# DECODER0_MSVDX_VDEB register map
Vendor: Texas Instruments
Peripheral module from a debugger description file (folder J7ES).
Registers are 32-bit, read-only, reset 0x0 unless marked. A register's access mark holds for its fields unless they carry their own. Offsets are as the file gives them; lines under a group give offsets from that group; [hi:lo] are bit positions; {n}, {i} and the like mark numbered series; 'fields as' and 'values as' point back to an identical list; <NAME> marks a mode.

## DECODER0_MSVDX_VDEB
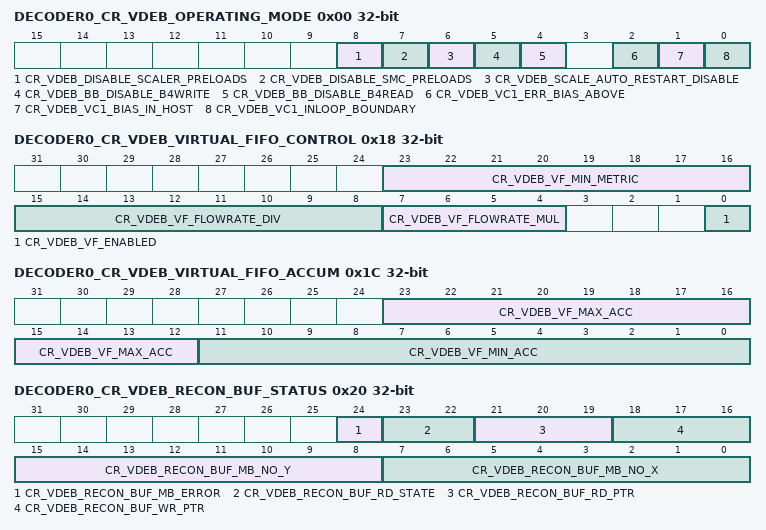
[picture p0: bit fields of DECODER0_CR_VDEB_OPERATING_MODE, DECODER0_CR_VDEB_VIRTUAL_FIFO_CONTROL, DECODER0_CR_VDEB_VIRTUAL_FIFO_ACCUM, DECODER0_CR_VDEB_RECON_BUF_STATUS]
0x00 DECODER0_CR_VDEB_OPERATING_MODE rw — VDEB operating mode. Used to alter operation implied by the codec mode
  [8] CR_VDEB_DISABLE_SCALER_PRELOADS — Disable MMU page preloads from the Alternative buffer [Scaler or rotation output]
  [7] CR_VDEB_DISABLE_SMC_PRELOADS — Disable MMU page preloads from the SMC.
  [6] CR_VDEB_SCALE_AUTO_RESTART_DISABLE — Disable Scaler auto restart.
  [5] CR_VDEB_BB_DISABLE_B4WRITE — Disable burst4 writes generated in the burst buffer.
  [4] CR_VDEB_BB_DISABLE_B4READ — Disable burst4 reads generated in the burst buffer.
  [2] CR_VDEB_VC1_ERR_BIAS_ABOVE — For error concealment force bias/clip of above data
  [1] CR_VDEB_VC1_BIAS_IN_HOST — Bias and clip filtering may be performed by the host or in hardware
  [0] CR_VDEB_VC1_INLOOP_BOUNDARY — VC1 In-loop boundary flags may be supplied via command for in-loop deblock filtering
0x04 DECODER0_CR_VDEB_PREFETCH_FIFO rw — VDEB Pre-fetch FIFO control and status
  [0] CR_VDEB_PREFETCH_FIFO_DISABLED — Use of Pre-fetch FIFO may be disabled for error handling
0x08 DECODER0_CR_VDEB_SYS_MEM_RDATA_LUMA_SIGNATURE
  [31:0] CR_VDEB_SYS_MEM_RDATA_LUMA_SIGNATURE — VDEB signature analysis on the system-memory luma read-data bus
0x0C DECODER0_CR_VDEB_SYS_MEM_RDATA_CHROMA_SIGNATURE
  [31:0] CR_VDEB_SYS_MEM_RDATA_CHROMA_SIGNATURE — VDEB signature analysis on the system-memory chroma read-data bus
0x10 DECODER0_CR_VDEB_SYS_MEM_ADDR_SIGNATURE — The address signature includes a base address id added to the bottom 3 bits of the signature input. The id is as follows 0x0: Chroma2 reconstructed 0x1: Luma reconstructed 0x2: Chroma reconstructed 0x3: Aux MSB buffer 0x4: Aux Line buffer 0x5: Luma alternate 0x6: Chroma alternate 0x7: Chroma2 alternate
  [31:0] CR_VDEB_SYS_MEM_ADDR_SIGNATURE — VDEB signature analysis on the system-memory address bus
0x14 DECODER0_CR_VDEB_SYS_MEM_WDATA_SIGNATURE
  [31:0] CR_VDEB_SYS_MEM_WDATA_SIGNATURE — VDEB signature analysis on the system-memory write-data bus
0x18 DECODER0_CR_VDEB_VIRTUAL_FIFO_CONTROL rw — The Virtual FIFO enables dynamic control of the 'Time to Expire' output for the system memory interface
  [23:16] CR_VDEB_VF_MIN_METRIC — The minimum value of the 'time to expire metric'
  [15:8] CR_VDEB_VF_FLOWRATE_DIV — Virtual FIFO divisor control.
  [7:4] CR_VDEB_VF_FLOWRATE_MUL — Virtual FIFO multiple control.
  [0] CR_VDEB_VF_ENABLED — Enable the Virtual FIFO
0x1C DECODER0_CR_VDEB_VIRTUAL_FIFO_ACCUM rw — Virtual FIFO flow rate accumulator defines the effective size and the number of words of deficit in the data flow that can be controlled
  [23:12] CR_VDEB_VF_MAX_ACC — Virtual FIFO max internal accumulator value defines the upper range for the accumulator which prevents the metric getting set unrealistically high
  [11:0] CR_VDEB_VF_MIN_ACC — Virtual FIFO min internal accumulator value defines the lower range for the accumulator, allowing a low priority to be applied to all
0x20 DECODER0_CR_VDEB_RECON_BUF_STATUS
  [24] CR_VDEB_RECON_BUF_MB_ERROR — Recon Buf MB Error flag - MB has been marked as with an error
  [23:22] CR_VDEB_RECON_BUF_RD_STATE — Recon Buf internal read state
  [21:19] CR_VDEB_RECON_BUF_RD_PTR — Recon Buf read pointer
  [18:16] CR_VDEB_RECON_BUF_WR_PTR — Recon Buf write pointer
  [15:8] CR_VDEB_RECON_BUF_MB_NO_Y — Recon Buf macroblock number Y
  [7:0] CR_VDEB_RECON_BUF_MB_NO_X — Recon Buf macroblock number X
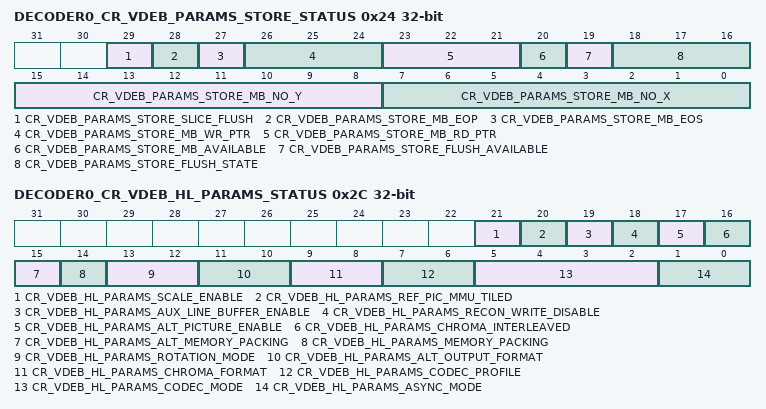
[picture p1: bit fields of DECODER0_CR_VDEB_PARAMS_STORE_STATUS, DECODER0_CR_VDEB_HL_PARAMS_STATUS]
0x24 DECODER0_CR_VDEB_PARAMS_STORE_STATUS
  [29] CR_VDEB_PARAMS_STORE_SLICE_FLUSH — Param Store slice flush
  [28] CR_VDEB_PARAMS_STORE_MB_EOP — Param Store macroblock end of picture
  [27] CR_VDEB_PARAMS_STORE_MB_EOS — Param Store macroblock end of slice
  [26:24] CR_VDEB_PARAMS_STORE_MB_WR_PTR — Param Store macroblock write pointer
  [23:21] CR_VDEB_PARAMS_STORE_MB_RD_PTR — Param Store macroblock read pointer
  [20] CR_VDEB_PARAMS_STORE_MB_AVAILABLE — Param Store macroblock available
  [19] CR_VDEB_PARAMS_STORE_FLUSH_AVAILABLE — Param Store flush available
  [18:16] CR_VDEB_PARAMS_STORE_FLUSH_STATE — Param Store Flush state
  [15:8] CR_VDEB_PARAMS_STORE_MB_NO_Y — Param Store macroblock number Y
  [7:0] CR_VDEB_PARAMS_STORE_MB_NO_X — Param Store macroblock number X
0x28 DECODER0_CR_VDEB_SLICE_INTERRUPT_COUNT — Register to keep track of interrupts generated
  [2:0] CR_VDEB_SLICE_INTERRUPT_COUNT — Wrapping counter incremented every end of slice interrupt
0x2C DECODER0_CR_VDEB_HL_PARAMS_STATUS — Register to keep track of internal setup programmed via firmware or otherwise inaccesible values:
  [21] CR_VDEB_HL_PARAMS_SCALE_ENABLE — Scale Enable
  [20] CR_VDEB_HL_PARAMS_REF_PIC_MMU_TILED — Ref Pic MMU Tiled
  [19] CR_VDEB_HL_PARAMS_AUX_LINE_BUFFER_ENABLE — Auxiliary Line Buffer Enable
  [18] CR_VDEB_HL_PARAMS_RECON_WRITE_DISABLE — Recon Write Disable
  [17] CR_VDEB_HL_PARAMS_ALT_PICTURE_ENABLE — Alternative Picture Enable
  [16] CR_VDEB_HL_PARAMS_CHROMA_INTERLEAVED — Chroma Interleaved
  [15] CR_VDEB_HL_PARAMS_ALT_MEMORY_PACKING — Alternative Memory Packing
  [14] CR_VDEB_HL_PARAMS_MEMORY_PACKING — Memory Packing
  [13:12] CR_VDEB_HL_PARAMS_ROTATION_MODE — Rotation Mode
  [11:10] CR_VDEB_HL_PARAMS_ALT_OUTPUT_FORMAT — Alternative Output Format
  [9:8] CR_VDEB_HL_PARAMS_CHROMA_FORMAT — Chroma Format
  [7:6] CR_VDEB_HL_PARAMS_CODEC_PROFILE — Codec Profile
  [5:2] CR_VDEB_HL_PARAMS_CODEC_MODE — Codec Mode
  [1:0] CR_VDEB_HL_PARAMS_ASYNC_MODE — Async Mode
0x30 DECODER0_CR_VDEB_BLOCK_MEM_DIAGNOSTICS
  [31:0] CR_VDEB_BLOCK_MEM_DIAGNOSTICS — VDEB block_mem diagnostics [debug use only]
0x34 DECODER0_CR_VDEB_PARAMS_DIAGNOSTICS
  [31:0] CR_VDEB_PARAMS_DIAGNOSTICS — VDEB param-store diagnostics [debug use only]
0x38 DECODER0_CR_VDEB_FILTER_DIAGNOSTICS
  [31:0] CR_VDEB_FILTER_DIAGNOSTICS — VDEB filter diagnostics [debug use only]
0x3C DECODER0_CR_VDEB_MAIN_DIAGNOSTICS reset 0xB000
  [31:0] CR_VDEB_MAIN_DIAGNOSTICS — VDEB main-control diagnostics [debug use only]
0x40 DECODER0_CR_VDEB_SYS_MEM_ADDR_WR_LUMA_SIGNATURE — The address signature includes a base address id added to the bottom 3 bits of the signature input. The id is as follows 0x1: Luma reconstructed 0x3: Aux MSB buffer 0x4: Aux Line buffer 0x5: Luma alternate
  [31:0] CR_VDEB_SYS_MEM_ADDR_WR_LUMA_SIGNATURE — VDEB signature analysis on the system-memory addr bus for luma
0x44 DECODER0_CR_VDEB_SYS_MEM_ADDR_WR_CHROMA_SIGNATURE — The address signature includes a base address id added to the bottom 3 bits of the signature input. The id is as follows 0x0: Chroma2 reconstructed 0x2: Chroma reconstructed 0x3: Aux MSB buffer 0x4: Aux Line buffer 0x6: Chroma alternate 0x7: Chroma2 alternate
  [31:0] CR_VDEB_SYS_MEM_ADDR_WR_CHROMA_SIGNATURE — VDEB signature analysis on the system-memory addr bus for chroma
0x48 DECODER0_CR_VDEB_SCALE_ADDR_SIGNATURE — The address signature includes a base address id added to the bottom 3 bits of the signature input. The id is as follows 0x0: Chroma2 reconstructed 0x1: Luma reconstructed 0x2: Chroma reconstructed 0x3: Aux MSB buffer 0x4: Aux Line buffer 0x5: Luma alternate 0x6: Chroma alternate 0x7: Chroma2 alternate
  [31:0] CR_VDEB_SCALE_ADDR_SIGNATURE — VDEB signature analysis on the scale address bus
0x4C DECODER0_CR_VDEB_SCALE_WDATA_SIGNATURE
  [31:0] CR_VDEB_SCALE_WDATA_SIGNATURE — VDEB signature analysis on the scale write-data bus
0x50 DECODER0_CR_VDEB_MULTICORE_DIAGNOSTICS
  [31:0] CR_VDEB_MULTICORE_DIAGNOSTICS — VDEB Multicore diagnostics [debug use only]
0x54 DECODER0_CR_VDEB_SYS_MEM_ADDR_RD_LUMA_SIGNATURE — The address signature includes a base address id added to the bottom 3 bits of the signature input. The id is as follows 0x1: Luma reconstructed 0x3: Aux MSB buffer 0x4: Aux Line buffer 0x5: Luma alternate
  [31:0] CR_VDEB_SYS_MEM_ADDR_RD_LUMA_SIGNATURE — VDEB signature analysis on the system-memory addr bus for luma
0x58 DECODER0_CR_VDEB_SYS_MEM_ADDR_RD_CHROMA_SIGNATURE — The address signature includes a base address id added to the bottom 3 bits of the signature input. The id is as follows 0x0: Chroma2 reconstructed 0x2: Chroma reconstructed 0x3: Aux MSB buffer 0x4: Aux Line buffer 0x6: Chroma alternate 0x7: Chroma2 alternate
  [31:0] CR_VDEB_SYS_MEM_ADDR_RD_CHROMA_SIGNATURE — VDEB signature analysis on the system-memory addr bus for chroma
0x5C DECODER0_CR_VDEB_NCORE_WDATA_SIGNATURE
  [31:0] CR_VDEB_NCORE_WDATA_SIGNATURE — VDEB signature analys for ncore data bus
0x60 DECODER0_CR_VDEB_HEVC_CHECKSUM_LUMA
  [31:0] CR_VDEB_HEVC_CHECKSUM_LUMA — A checksum on luma plane pixels caculated in the same way as 'picture_checksum' used in HEVC Decoded picture hash SEI message
0x64 DECODER0_CR_VDEB_HEVC_CHECKSUM_CB
  [31:0] CR_VDEB_HEVC_CHECKSUM_CB — A checksum on Cb plane pixels caculated in the same way as 'picture_checksum' used in HEVC Decoded picture hash SEI message
0x68 DECODER0_CR_VDEB_HEVC_CHECKSUM_CR
  [31:0] CR_VDEB_HEVC_CHECKSUM_CR — A checksum on Cr plane pixels caculated in the same way as 'picture_checksum' used in HEVC Decoded picture hash SEI message
0x6C DECODER0_CR_VDEB_SCALE_PRELOAD_ADDR_SIGNATURE
  [31:0] CR_VDEB_SCALE_PRELOAD_ADDR_SIGNATURE — VDEB signature analys for scaler write address bus when doing preload
0x70 DECODER0_CR_VDEB_SYS_MEM_PRELOAD_ADDR_WR_SIGNATURE
  [31:0] CR_VDEB_SYS_MEM_PRELOAD_ADDR_WR_SIGNATURE — VDEB signature analys on sys mem write address bus when doing preload
